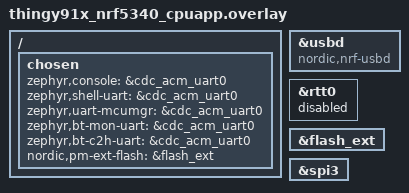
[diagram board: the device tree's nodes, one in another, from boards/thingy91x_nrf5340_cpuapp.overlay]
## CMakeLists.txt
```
#
# Copyright (c) 2022 Nordic Semiconductor ASA
#
# SPDX-License-Identifier: LicenseRef-Nordic-5-Clause
#

cmake_minimum_required(VERSION 3.20.0)

find_package(Zephyr REQUIRED HINTS $ENV{ZEPHYR_BASE})
project(nrf_wifi_sta)

target_include_directories(app PUBLIC ${ZEPHYR_BASE}/subsys/net/ip)

# Add http service
zephyr_linker_sources(SECTIONS sections-rom.ld)
zephyr_linker_section_ifdef(CONFIG_NET_SAMPLE_HTTP_SERVICE NAME
				http_resource_desc_test_http_service
				KVMA RAM_REGION GROUP RODATA_REGION
				SUBALIGN Z_LINK_ITERABLE_SUBALIGN)

# Add static web resources
set(gen_dir ${ZEPHYR_BINARY_DIR}/include/generated/)

foreach(web_resource
  index.html
  main.js
  styles.css
  Color_circle.svg
  Logo_Flat_RGB_Horizontal.svg
  thingy91x.glb
    )
  generate_inc_file_for_target(
    app
    src/static_web_resources/${web_resource}
    ${gen_dir}/${web_resource}.gz.inc
    --gzip
  )
endforeach()

# Generate hex files from pem files
set(gen_dir ${CMAKE_CURRENT_BINARY_DIR}/certs)
zephyr_include_directories(${gen_dir})
generate_inc_file_for_target(
    app
    cert/StarfieldServicesCertG2.pem
    ${gen_dir}/StarfieldServicesCertG2.pem.inc
    )

target_sources(app PRIVATE
	src/main.c
    src/sensors.c
    src/http_resources.c
    src/wifi.c
    src/https_request.c
)
```

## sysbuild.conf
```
#
# Copyright (c) 2024 Nordic Semiconductor ASA
#
# SPDX-License-Identifier: LicenseRef-Nordic-5-Clause
#

SB_CONFIG_WIFI_NRF70=y

SB_CONFIG_THINGY91X_STATIC_PARTITIONS_NRF53_EXTERNAL_FLASH=y
```

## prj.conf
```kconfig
#
# Copyright (c) 2024 Nordic Semiconductor ASA
#
# SPDX-License-Identifier: LicenseRef-Nordic-5-Clause
#

# Optimize TF-M
CONFIG_TFM_PROFILE_TYPE_SMALL=y
CONFIG_PM_PARTITION_SIZE_TFM_SRAM=0xa000
CONFIG_PM_PARTITION_SIZE_TFM=0x20000

# Optimize Wi-Fi stack to save some memory.
CONFIG_HEAP_MEM_POOL_SIZE=120000
CONFIG_HEAP_MEM_POOL_IGNORE_MIN=y
CONFIG_NRF70_RX_NUM_BUFS=16
CONFIG_NRF70_MAX_TX_AGGREGATION=4

# Wi-Fi
CONFIG_WIFI=y
CONFIG_WIFI_NRF70=y
CONFIG_NRF70_AP_MODE=y
CONFIG_WIFI_NM_WPA_SUPPLICANT=y
CONFIG_WIFI_NM_WPA_SUPPLICANT_AP=y
CONFIG_NET_L2_ETHERNET=y
CONFIG_WIFI_CREDENTIALS=y

# General
CONFIG_LOG=y
CONFIG_LOG_MODE_IMMEDIATE=y
CONFIG_ASSERT=y
CONFIG_ASSERT_VERBOSE=n
CONFIG_REBOOT=y

CONFIG_NET_LOG=y
CONFIG_LOG_DEFAULT_LEVEL=3


# Link-time optimizations
CONFIG_LTO=y
CONFIG_ISR_TABLES_LOCAL_DECLARATION=y

# Temporarily enable FS support so that linking succeeds.
CONFIG_FILE_SYSTEM=y
CONFIG_MAIN_STACK_SIZE=6144
CONFIG_NANOPB=y
CONFIG_SMF=y

# HTTP parser
CONFIG_HTTP_PARSER=y
CONFIG_HTTP_PARSER_URL=y

# DK Butons and LEDs
CONFIG_DK_LIBRARY=y

# Networking config
CONFIG_NETWORKING=y
CONFIG_NET_CONNECTION_MANAGER=y
CONFIG_NET_IPV4=y
# Disable IPv6 to save memory
CONFIG_NET_IPV6=n
CONFIG_NET_TCP=y
CONFIG_NET_UDP=y
CONFIG_NET_SOCKETS=y
CONFIG_NET_MAX_CONN=6
CONFIG_ZVFS_OPEN_MAX=20
CONFIG_NET_SOCKETS_TLS_MAX_CONTEXTS=2
CONFIG_NET_SOCKETS_SOCKOPT_TLS=y

# Zephyr NET Connection Manager connectivity layer
CONFIG_L2_WIFI_CONNECTIVITY=y
CONFIG_L2_WIFI_CONNECTIVITY_AUTO_CONNECT=n
CONFIG_L2_WIFI_CONNECTIVITY_AUTO_DOWN=n

# SoftAP Wi-Fi Provision library
CONFIG_SOFTAP_WIFI_PROVISION=y
CONFIG_SOFTAP_WIFI_PROVISION_THREAD_STACK_SIZE=8192
# Disable socket close on completed provisioning to keep mDNS SD running.
# SD depends on the socket being open for a specified port.
CONFIG_SOFTAP_WIFI_PROVISION_SOCKET_CLOSE_ON_COMPLETION=n
CONFIG_SOFTAP_WIFI_PROVISION_LOG_LEVEL_DBG=y

# (M)DNS
CONFIG_MDNS_RESPONDER=y
CONFIG_DNS_SD=y
CONFIG_MDNS_RESPONDER_DNS_SD=y
CONFIG_NET_HOSTNAME_ENABLE=y
CONFIG_NET_HOSTNAME="wifiprov"
# Disable POSIX uname support to suppress build warning that hostname is too long.
CONFIG_POSIX_UNAME=n

# DHCPv4 client and server
CONFIG_NET_DHCPV4=y
CONFIG_NET_DHCPV4_SERVER=y

# Store TLS credentials to protected storage.
CONFIG_TLS_CREDENTIALS=y
CONFIG_TLS_CREDENTIALS_BACKEND_PROTECTED_STORAGE=y

# Disable auto init of NET config as the softAP Wi-Fi provision library will manually set its
# own IP configuration.
CONFIG_NET_CONFIG_AUTO_INIT=n


CONFIG_FLASH=y
CONFIG_FLASH_MAP=y
CONFIG_NVS=y
CONFIG_SETTINGS=y
CONFIG_SETTINGS_NVS=y
```

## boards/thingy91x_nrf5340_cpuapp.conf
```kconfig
CONFIG_SPI=y
CONFIG_FLASH=y
CONFIG_SPI_NOR=y
CONFIG_SPI_NOR_FLASH_LAYOUT_PAGE_SIZE=4096
CONFIG_SPI_NOR_SFDP_DEVICETREE=y
CONFIG_I2C=y

CONFIG_NFCT_PINS_AS_GPIOS=y


# USB
CONFIG_USB_DEVICE_STACK=y
CONFIG_USB_DEVICE_PRODUCT="Thingy:91x USB Logging"
CONFIG_USB_CDC_ACM=y
CONFIG_USB_COMPOSITE_DEVICE=y
CONFIG_USB_MASS_STORAGE=n
CONFIG_USB_DEVICE_MANUFACTURER="Nordic Semiconductor"
CONFIG_USB_DEVICE_VID=0x1915
CONFIG_USB_DEVICE_PID=0x910A

CONFIG_USB_DEVICE_REMOTE_WAKEUP=n
CONFIG_USB_DEVICE_INITIALIZE_AT_BOOT=y

CONFIG_USE_SEGGER_RTT=n
CONFIG_RTT_CONSOLE=n

CONFIG_FW_INFO=y
CONFIG_SECURE_BOOT_STORAGE=y


CONFIG_FLASH=y
CONFIG_FLASH_MAP=y
CONFIG_NVS=y
CONFIG_SETTINGS=y
CONFIG_SETTINGS_NVS=y
```

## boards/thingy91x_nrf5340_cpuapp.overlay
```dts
/* Copyright (c) 2024 Nordic Semiconductor ASA
 *
 * SPDX-License-Identifier: LicenseRef-Nordic-5-Clause
 */

 #include <thingy91x_nrf53_wifi.dtsi>

 &usbd {
     compatible = "nordic,nrf-usbd";
     status = "okay";
 };
 
 / {
     chosen {
         zephyr,console = &cdc_acm_uart0;
         zephyr,shell-uart = &cdc_acm_uart0;
         zephyr,uart-mcumgr = &cdc_acm_uart0;
         zephyr,bt-mon-uart = &cdc_acm_uart0;
         zephyr,bt-c2h-uart = &cdc_acm_uart0;
         nordic,pm-ext-flash = &flash_ext;
     };
 };
 
 &rtt0 {
     status = "disabled";
 };
 
 
 /* Enable external flash */
 &flash_ext{
     status = "okay";
 };
 
 &spi3{
     status = "okay";
 };
```

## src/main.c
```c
/*
 * Copyright (c) 2022 Nordic Semiconductor ASA
 *
 * SPDX-License-Identifier: LicenseRef-Nordic-5-Clause
 */

/** @file
 * @brief WiFi station sample
 */

#include <zephyr/logging/log.h>
LOG_MODULE_REGISTER(http_server, CONFIG_LOG_DEFAULT_LEVEL);

#include <zephyr/kernel.h>
#include <stdio.h>
#include <stdlib.h>
#include <zephyr/shell/shell.h>
#include <zephyr/init.h>

#include <dk_buttons_and_leds.h>
#include <zephyr/device.h>
#include <zephyr/drivers/pwm.h>

#include <zephyr/data/json.h>

#include <zephyr/net/socket.h>
#include <zephyr/net/websocket.h>

#include <zephyr/sys/reboot.h>

#include "sensors.h"
#include "http_resources.h"
#include "wifi.h"
#include "https_request.h"

#ifdef CONFIG_SYS_HEAP_LISTENER
#include <zephyr/sys/heap_listener.h>
extern struct sys_heap _system_heap;
struct sys_memory_stats system_heap_stats;
uint32_t system_heap_free = 0;
uint32_t system_heap_used = 0;
uint32_t system_heap_max_used = 0;

void on_system_heap_alloc(uintptr_t heap_id, void *mem, size_t bytes)
{
	if (heap_id == HEAP_ID_FROM_POINTER(&_system_heap)) {
		sys_heap_runtime_stats_get((struct sys_heap *)&_system_heap.heap,
					   &system_heap_stats);
		system_heap_used = (uint32_t)system_heap_stats.allocated_bytes;
		system_heap_max_used = (uint32_t)system_heap_stats.max_allocated_bytes;
		system_heap_free = (uint32_t)system_heap_stats.free_bytes;
		LOG_INF("system_heap ALLOC %zu. Heap state: allocated %zu, free %zu, max allocated "
			"%zu, heap size %u.\n",
			bytes, system_heap_used, system_heap_free, system_heap_max_used,
			K_HEAP_MEM_POOL_SIZE);
	}
}

void on_system_heap_free(uintptr_t heap_id, void *mem, size_t bytes)
{
	if (heap_id == HEAP_ID_FROM_POINTER(&_system_heap)) {
		sys_heap_runtime_stats_get((struct sys_heap *)&_system_heap.heap,
					   &system_heap_stats);
		system_heap_used = (uint32_t)system_heap_stats.allocated_bytes;
		system_heap_max_used = (uint32_t)system_heap_stats.max_allocated_bytes;
		system_heap_free = (uint32_t)system_heap_stats.free_bytes;
		LOG_INF("system_heap ALLOC %zu. Heap state: allocated %zu, free %zu, max allocated "
			"%zu, heap size %u.\n",
			bytes, system_heap_used, system_heap_free, system_heap_max_used,
			K_HEAP_MEM_POOL_SIZE);
	}
}

HEAP_LISTENER_ALLOC_DEFINE(system_heap_listener_alloc, HEAP_ID_FROM_POINTER(&_system_heap),
			   on_system_heap_alloc);
HEAP_LISTENER_FREE_DEFINE(system_heap_listener_free, HEAP_ID_FROM_POINTER(&_system_heap),
			  on_system_heap_free);
#endif // CONFIG_SYS_HEAP_LISTENER

static const struct pwm_dt_spec red_pwm_led = PWM_DT_SPEC_GET(DT_ALIAS(pwm_led0));
static const struct pwm_dt_spec green_pwm_led = PWM_DT_SPEC_GET(DT_ALIAS(pwm_led1));
static const struct pwm_dt_spec blue_pwm_led = PWM_DT_SPEC_GET(DT_ALIAS(pwm_led2));

uint8_t apply_gamma(uint8_t value, float gamma)
{
	/* (value/255)^gamma * 255 */
	return (uint8_t)(pow(value / 255.0, gamma) * 255);
}

int pwm_set_color(int red, int green, int blue)
{
	int ret;

	/* Parameters to adjust intensity of each color */
	float red_gamma = 2.2;
	float green_gamma = 2.2;
	float blue_gamma = 2.2;

	float red_intensity_scale = 1.0;
	float green_intensity_scale = 1.0;
	float blue_intensity_scale = 0.8;

	// LOG_DBG("PWM_Color: Red: %d, Green: %d, Blue: %d \n", red, green, blue);

	// Apply gamma correction
	int corrected_red = apply_gamma(red * red_intensity_scale, red_gamma);
	int corrected_green = apply_gamma(green * green_intensity_scale, green_gamma);
	int corrected_blue = apply_gamma(blue * blue_intensity_scale, blue_gamma);

	// uint32_t period = red_pwm_led.period;
	int pwm_red = (corrected_red * red_pwm_led.period) / 255;
	int pwm_green = (corrected_green * green_pwm_led.period) / 255;
	int pwm_blue = (corrected_blue * blue_pwm_led.period) / 255;

	ret = pwm_set_pulse_dt(&red_pwm_led, pwm_red);
	if (ret != 0) {
		LOG_ERR("Error %d: red write failed\n", ret);
		return ret;
	}

	ret = pwm_set_pulse_dt(&green_pwm_led, pwm_green);
	if (ret != 0) {
		LOG_ERR("Error %d: green write failed\n", ret);
		return ret;
	}

	ret = pwm_set_pulse_dt(&blue_pwm_led, pwm_blue);
	if (ret != 0) {
		LOG_ERR("Error %d: blue write failed\n", ret);
		return ret;
	}

	return 0;
}

static void sensor_handler(struct k_work *work)
{
	int ret;
	static char tx_buf[1024];
	struct k_work_delayable *dwork = k_work_delayable_from_work(work);
	struct ws_sensors_ctx *ctx = CONTAINER_OF(dwork, struct ws_sensors_ctx, work);

	// ret = sensors_collect(tx_buf, sizeof(tx_buf));
	ret = sensors_get_json(tx_buf, sizeof(tx_buf));
	if (ret < 0) {
		LOG_ERR("Unable to collect sensor data, err %d", ret);
		goto unregister;
	}

	ret = websocket_send_msg(ctx->sock, tx_buf, ret, WEBSOCKET_OPCODE_DATA_TEXT, false, true,
				 SYS_FOREVER_MS);
	if (ret < 0) {
		LOG_INF("Couldn't send websocket msg (%d), closing connection", ret);
		goto unregister;
	}

	ret = k_work_reschedule(&ctx->work, K_MSEC(CONFIG_NET_SAMPLE_WEBSOCKET_SENSOR_INTERVAL));
	if (ret < 0) {
		LOG_ERR("Failed to schedule sensor work, err %d", ret);
		goto unregister;
	}

	return;

unregister:
	(void)websocket_unregister(ctx->sock);
	ctx->sock = -1;
}

int ws_sensors_init(void)
{
	struct ws_sensors_ctx *ctx = NULL;
	http_resources_get_ws_ctx(&ctx);

	for (int i = 0; i < CONFIG_NET_SAMPLE_NUM_WEBSOCKET_HANDLERS; i++) {
		ctx[i].sock = -1;
		k_work_init_delayable(&ctx[i].work, sensor_handler);
	}

	return 0;
}
SYS_INIT(ws_sensors_init, APPLICATION, 0);

static int get_free_sensor_slot(void)
{
	struct ws_sensors_ctx *ctx = NULL;
	http_resources_get_ws_ctx(&ctx);

	for (int i = 0; i < CONFIG_NET_SAMPLE_NUM_WEBSOCKET_HANDLERS; i++) {
		if (ctx[i].sock < 0) {
			return i;
		}
	}

	return -1;
}

int ws_sensors_setup(int ws_socket, void *user_data)
{
	ARG_UNUSED(user_data);

	struct ws_sensors_ctx *ctx = NULL;
	http_resources_get_ws_ctx(&ctx);

	int slot = get_free_sensor_slot();
	if (slot < 0) {
		LOG_ERR("No free slot for sensor websocket");
		return -ENOMEM;
	}
	LOG_INF("Setting up sensor websocket on slot %d", slot);

	ctx[slot].sock = ws_socket;

	LOG_INF("Using socket %d for sensor websocket", ws_socket);

	int ret = k_work_reschedule(&ctx[slot].work, K_NO_WAIT);
	if (ret < 0) {
		LOG_ERR("Failed to reschedule sensor work");
		return ret;
	}

	LOG_INF("Sensor websocket setup on slot %d", slot);

	return 0;
}

static void parse_led_post(uint8_t *buf, size_t len)
{
	int ret;
	struct led_command cmd;
	const int expected_return_code = BIT_MASK(ARRAY_SIZE(led_command_descr));

	LOG_DBG("Got POST request with payload: %s", buf);

	ret = json_obj_parse(buf, len, led_command_descr, ARRAY_SIZE(led_command_descr), &cmd);
	if (ret != expected_return_code) {
		LOG_WRN("Failed to fully parse JSON payload, ret=%d", ret);
		return;
	}

	ret = pwm_set_color(cmd.r, cmd.g, cmd.b);
	if (ret) {
		LOG_ERR("Failed to set LED color");
	}
}

static int led_handler(struct http_client_ctx *client, enum http_data_status status,
		       uint8_t *buffer, size_t len, void *user_data)
{
	ARG_UNUSED(client);
	ARG_UNUSED(user_data);

	static uint8_t post_payload_buf[32];
	static size_t cursor;

	LOG_DBG("LED handler status %d, size %zu", status, len);

	if (status == HTTP_SERVER_DATA_ABORTED) {
		cursor = 0;
		return 0;
	}

	if (len + cursor > sizeof(post_payload_buf)) {
		cursor = 0;
		return -ENOMEM;
	}

	/* Copy payload to our buffer. Note that even for a small payload, it may arrive split into
	 * chunks (e.g. if the header size was such that the whole HTTP request exceeds the size of
	 * the client buffer).
	 */
	memcpy(post_payload_buf + cursor, buffer, len);
	cursor += len;

	if (status == HTTP_SERVER_DATA_FINAL) {
		parse_led_post(post_payload_buf, cursor);
		cursor = 0;
	}

	return 0;
}

static void parse_jwt_post(uint8_t *buf, size_t len)
{
	ARG_UNUSED((len));

	int ret;

	ret = pwm_set_color(255, 255, 0);
	if (ret) {
		LOG_ERR("Failed to set LED color");
	}

	// Manually phrasing the JSON payload
	char temp_buff[512] = {0};
	// Remove leading {"jwt":"
	ret = snprintf(temp_buff, sizeof(temp_buff), "%s", buf + 8);
	if (ret < 0) {
		LOG_ERR("Failed to format JWT\n");
		return;
	}
	// Remove trailing "}
	temp_buff[ret - 2] = '\0';

	char location_str[256];
	memset(location_str, 0, sizeof(location_str));

	char api_str[CONFIG_WIFI_SCAN_STR_MAX_MAC_ADDR * 65];

	get_nrfcloud_api_str(api_str, sizeof(api_str));

	send_http_request(location_str, sizeof(location_str), api_str, sizeof(api_str), temp_buff);

	http_resources_set_location(location_str);

	ret = pwm_set_color(0, 255, 0);
	if (ret) {
		LOG_ERR("Failed to set LED color");
	}
}

static int jwt_handler(struct http_client_ctx *client, enum http_data_status status,
		       uint8_t *buffer, size_t len, void *user_data)
{

	ARG_UNUSED(client);
	ARG_UNUSED(user_data);

	static uint8_t post_payload_buf[512];
	static size_t cursor;

	if (status == HTTP_SERVER_DATA_ABORTED) {
		cursor = 0;
		return 0;
	}

	if (len + cursor > sizeof(post_payload_buf)) {
		cursor = 0;
		LOG_ERR("Buffer overflow");
		return -ENOMEM;
	}

	/* Copy payload to our buffer. Note that even for a small payload, it may arrive split into
	 * chunks (e.g. if the header size was such that the whole HTTP request exceeds the size of
	 * the client buffer).
	 */
	memcpy(post_payload_buf + cursor, buffer, len);
	cursor += len;
	LOG_INF("JWT handler cursor %zu", cursor);

	if (status == HTTP_SERVER_DATA_FINAL) {
		parse_jwt_post(post_payload_buf, cursor);
		memset(post_payload_buf, 0, sizeof(post_payload_buf));
		// Clear the buffer after processing
		cursor = 0;
	}

	return 0;
}

/**
 * @brief Function called when buttons are pressed.
 */
static void button_handler(uint32_t button_state, uint32_t has_changed)
{
	if (has_changed & DK_BTN1_MSK) {
		if (button_state & DK_BTN1_MSK) {
			LOG_INF("Button 1 pressed");
			sys_reboot(SYS_REBOOT_COLD); // Reset the device
		}
	}
}

/**
 * @brief Function called when Wi-Fi is connected.
 */
static void wifi_connected_handler(void)
{
	LOG_INF("Wi-Fi connected");

	LOG_INF("HTTP server staring");
	http_server_start();

	int ret = pwm_set_color(0, 255, 0);
	if (ret) {
		LOG_ERR("Failed to set LED color");
	}
}

static int location_handler(struct http_client_ctx *client, enum http_data_status status,
			    uint8_t *buffer, size_t len, void *user_data)
{
	ARG_UNUSED(client);
	ARG_UNUSED(len);
	ARG_UNUSED(user_data);

	static bool response_sent;
	extern char location_buf[256];

	switch (status) {
	case HTTP_SERVER_DATA_ABORTED: {
		response_sent = false;
		return 0;
	}

	case HTTP_SERVER_DATA_MORE: {
		/* A payload is not expected with the GET request. Ignore any data and wait until
		 * final callback before sending response
		 */
		return 0;
	}

	case HTTP_SERVER_DATA_FINAL: {
		if (response_sent) {
			/* Response already sent, return 0 to indicate to server that the callback
			 * does not need to be called again.
			 */
			response_sent = false;
			return 0;
		}

		response_sent = true;
		return snprintf(buffer, sizeof(location_buf), "%s", location_buf);
	}
	default: {
		LOG_WRN("Unexpected status %d", status);
		return -1;
	}
	}
}

int main(void)
{
	int ret = 0;

	// ret = dk_leds_init();
	// if (ret != 0) {
	// 	LOG_ERR("Failed to initialize LEDs");
	// 	return -1;
	// }

	if (!pwm_is_ready_dt(&red_pwm_led) || !pwm_is_ready_dt(&green_pwm_led) ||
	    !pwm_is_ready_dt(&blue_pwm_led)) {
		LOG_ERR("Error: one or more PWM devices not ready\n");
		return 0;
	}

	ret = pwm_set_color(255, 0, 0);
	if (ret) {
		LOG_ERR("Failed to set LED color");
	}

	ret = dk_buttons_init(button_handler);
	if (ret != 0) {
		LOG_ERR("Failed to initialize buttons");
		return -1;
	}

	ret = sensors_init();
	if (ret) {
		LOG_ERR("Failed to initialize sensors");
		return ret;
	}

	/* Provision certificates before connecting to the network */
	ret = cert_provision();
	if (ret) {
		return 0;
	}

	http_resources_set_led_handler(led_handler);
	http_resources_set_jwt_handler(jwt_handler);
	http_resources_set_ws_handler(ws_sensors_setup);
	wifi_sta_set_wifi_connected_cb(wifi_connected_handler);
	http_resources_set_location_handler(location_handler);

#ifdef CONFIG_SYS_HEAP_LISTENER
	heap_listener_register(&system_heap_listener_alloc);
	heap_listener_register(&system_heap_listener_free);
#endif // CONFIG_SYS_HEAP_LISTENER

	net_mgmt_callback_init();

	ret = wifi_scan();
	if (ret) {
		LOG_ERR("Failed to scan for Wi-Fi networks, err %d", ret);
		return ret;
	}

#ifdef CONFIG_WIFI_READY_LIB
	ret = register_wifi_ready();
	if (ret) {
		return ret;
	}
	k_thread_start(wifi_sta_get_start_wifi_thread_id());
#else
	start_app();
#endif /* CONFIG_WIFI_READY_LIB */

	return ret;
}
```

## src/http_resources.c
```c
#include "http_resources.h"

//////////////////////////////////////// HTTP Service //////////////////////////////////////////

static uint16_t test_http_service_port = CONFIG_NET_SAMPLE_HTTP_SERVER_SERVICE_PORT;
HTTP_SERVICE_DEFINE(test_http_service, NULL, &test_http_service_port, 1, 10, NULL);

//////////////////////////////////////// HTTP Resources //////////////////////////////////////////

////////////////// Index HTML //////////////////
// This is the main HTML file that is loaded by the browser.

static const uint8_t index_html_gz[] = {
#include "index.html.gz.inc"
};

struct http_resource_detail_static index_html_gz_resource_detail = {
	.common =
		{
			.type = HTTP_RESOURCE_TYPE_STATIC,
			.bitmask_of_supported_http_methods = BIT(HTTP_GET),
			.content_encoding = "gzip",
			.content_type = "text/html",
		},
	.static_data = index_html_gz,
	.static_data_len = sizeof(index_html_gz),
};

HTTP_RESOURCE_DEFINE(index_html_gz_resource, test_http_service, "/",
		     &index_html_gz_resource_detail);

////////////////// Main JS //////////////////
// This is the main JavaScript file that is loaded by the index.html file.

static const uint8_t main_js_gz[] = {
#include "main.js.gz.inc"
};

struct http_resource_detail_static main_js_gz_resource_detail = {
	.common =
		{
			.type = HTTP_RESOURCE_TYPE_STATIC,
			.bitmask_of_supported_http_methods = BIT(HTTP_GET),
			.content_encoding = "gzip",
			.content_type = "application/javascript",
		},
	.static_data = main_js_gz,
	.static_data_len = sizeof(main_js_gz),
};

HTTP_RESOURCE_DEFINE(main_js_gz_resource, test_http_service, "/main.js",
		     &main_js_gz_resource_detail);

////////////////// styles CSS //////////////////
// This is the CSS file that is loaded by the index.html file.

static const uint8_t styles_css_gz[] = {
#include "styles.css.gz.inc"
};

struct http_resource_detail_static styles_css_gz_resource_detail = {
	.common =
		{
			.type = HTTP_RESOURCE_TYPE_STATIC,
			.bitmask_of_supported_http_methods = BIT(HTTP_GET),
			.content_encoding = "gzip",
			.content_type = "text/css",
		},
	.static_data = styles_css_gz,
	.static_data_len = sizeof(styles_css_gz),
};

HTTP_RESOURCE_DEFINE(styles_css_gz_resource, test_http_service, "/styles.css",
		     &styles_css_gz_resource_detail);

////////////////// Color circle svg //////////////////
// This is an image to be displayed in the browser.

static const uint8_t color_circle_gz[] = {
#include "Color_circle.svg.gz.inc"
};

struct http_resource_detail_static color_circle_gz_resource_detail = {
	.common =
		{
			.type = HTTP_RESOURCE_TYPE_STATIC,
			.bitmask_of_supported_http_methods = BIT(HTTP_GET),
			.content_encoding = "gzip",
			.content_type = "image/svg+xml",
		},
	.static_data = color_circle_gz,
	.static_data_len = sizeof(color_circle_gz),
};

HTTP_RESOURCE_DEFINE(color_circle_gz_resource, test_http_service, "/Color_circle.svg",
		     &color_circle_gz_resource_detail);

////////////////// Logo Nordic svg //////////////////
// This is an image to be displayed in the browser.

static const uint8_t logo_Nordic_svg_gz[] = {
#include "Logo_Flat_RGB_Horizontal.svg.gz.inc"
};

struct http_resource_detail_static logo_Nordic_svg_gz_resource_detail = {
	.common =
		{
			.type = HTTP_RESOURCE_TYPE_STATIC,
			.bitmask_of_supported_http_methods = BIT(HTTP_GET),
			.content_encoding = "gzip",
			.content_type = "image/svg+xml",
		},
	.static_data = logo_Nordic_svg_gz,
	.static_data_len = sizeof(logo_Nordic_svg_gz),
};

HTTP_RESOURCE_DEFINE(logo_Nordic_svg_gz_resource, test_http_service,
		     "/Logo_Flat_RGB_Horizontal.svg", &logo_Nordic_svg_gz_resource_detail);

////////////////// 3D Model //////////////////
// This is an 3D model to be displayed in the browser.

static const uint8_t model_glb_gz[] = {
// #include "Duck.glb.gz.inc"
#include "thingy91x.glb.gz.inc"
};

struct http_resource_detail_static model_glb_gz_resource_detail = {
	.common =
		{
			.type = HTTP_RESOURCE_TYPE_STATIC,
			.bitmask_of_supported_http_methods = BIT(HTTP_GET),
			.content_encoding = "gzip",
			.content_type = "model/gltf-binary",
		},
	.static_data = model_glb_gz,
	.static_data_len = sizeof(model_glb_gz),
};

HTTP_RESOURCE_DEFINE(model_glb_gz_resource, test_http_service, "/thingy91x.glb",
		     &model_glb_gz_resource_detail);

////////////////// LED Resource //////////////////
// This is the resource that is used to control the LEDs on the Thingy:91x.
// It is a dynamic resource that accepts POST requests with JSON payloads.

static uint8_t led_buf[256]; // Buffer to store the JSON payload

static struct http_resource_detail_dynamic led_resource_detail = {
	.common =
		{
			.type = HTTP_RESOURCE_TYPE_DYNAMIC,
			.bitmask_of_supported_http_methods = BIT(HTTP_POST),
		},
	.cb = NULL, // This is set by the http_resources_set_led_handler function to allow callback
		    // function to be defined in main.c
	.data_buffer = led_buf,
	.data_buffer_len = sizeof(led_buf),
	.user_data = NULL,
};

HTTP_RESOURCE_DEFINE(led_resource, test_http_service, "/led", &led_resource_detail);

void http_resources_set_led_handler(http_resource_dynamic_cb_t handler)
{
	led_resource_detail.cb = handler;
}

///////////////////// JWT Resource //////////////////
// This is the resource that is used to get the JWT token from the server.
// It is a dynamic resource that accepts POST requests with JSON payloads.

static uint8_t jwt_buf[512]; // Buffer to store the JSON payload
static struct http_resource_detail_dynamic jwt_resource_detail = {
	.common =
		{
			.type = HTTP_RESOURCE_TYPE_DYNAMIC,
			.bitmask_of_supported_http_methods = BIT(HTTP_POST),
		},
	.cb = NULL, // This is set by the http_resources_set_jwt_handler function to allow callback
		    // function to be defined in main.c
	.data_buffer = jwt_buf,
	.data_buffer_len = sizeof(jwt_buf),
	.user_data = NULL,
};

HTTP_RESOURCE_DEFINE(jwt_resource, test_http_service, "/jwt", &jwt_resource_detail);

void http_resources_set_jwt_handler(http_resource_dynamic_cb_t handler)
{
	jwt_resource_detail.cb = handler;
}

////////////////// WebSocket Resource //////////////////
// This is the resource that is used to send sensor data over a WebSocket connection.

static struct ws_sensors_ctx sensors_ctx[CONFIG_NET_SAMPLE_NUM_WEBSOCKET_HANDLERS];

static uint8_t ws_netstats_buffer[128];

struct http_resource_detail_websocket ws_netstats_resource_detail = {
	.common =
		{
			.type = HTTP_RESOURCE_TYPE_WEBSOCKET,
			/* We need HTTP/1.1 Get method for upgrading */
			.bitmask_of_supported_http_methods = BIT(HTTP_GET),
		},
	.cb = NULL, // This is set by the http_resources_set_ws_handler function to allow callback
		    // function to be defined in main.c
	.data_buffer = ws_netstats_buffer,
	.data_buffer_len = sizeof(ws_netstats_buffer),
	.user_data = NULL,
};

HTTP_RESOURCE_DEFINE(ws_netstats_resource, test_http_service, "/", &ws_netstats_resource_detail);

void http_resources_set_ws_handler(http_resource_websocket_cb_t handler)
{
	ws_netstats_resource_detail.cb = handler;
}

void http_resources_get_ws_ctx(struct ws_sensors_ctx **ctx)
{
	*ctx = sensors_ctx;
}

////////////////// Location Resource //////////////////
// GET /location
// This is a dynamic resource that returns the location of the device.

uint8_t location_buf[256]; // Buffer to store the location

static struct http_resource_detail_dynamic location_resource_detail = {
	.common =
		{
			.type = HTTP_RESOURCE_TYPE_DYNAMIC,
			.bitmask_of_supported_http_methods = BIT(HTTP_GET),
		},
	.cb = NULL, // This is set by the http_resources_set_location_handler function to allow
		    // callback function to be defined in main.c
	.data_buffer = location_buf,
	.data_buffer_len = sizeof(location_buf),
	.user_data = NULL,
};

HTTP_RESOURCE_DEFINE(location_resource, test_http_service, "/location", &location_resource_detail);

void http_resources_set_location_handler(http_resource_dynamic_cb_t handler)
{
	location_resource_detail.cb = handler;
}

void http_resources_set_location(const char *location)
{
	strncpy(location_buf, location, sizeof(location_buf));
}
```

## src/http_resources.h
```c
#pragma once

#include <zephyr/net/http/server.h>
#include <zephyr/net/http/service.h>
#include <zephyr/data/json.h>

struct ws_sensors_ctx {
	int sock;
	struct k_work_delayable work;
};

struct led_command {
	int r;
	int g;
	int b;
};

static const struct json_obj_descr led_command_descr[] = {
	JSON_OBJ_DESCR_PRIM(struct led_command, r, JSON_TOK_NUMBER),
	JSON_OBJ_DESCR_PRIM(struct led_command, g, JSON_TOK_NUMBER),
	JSON_OBJ_DESCR_PRIM(struct led_command, b, JSON_TOK_NUMBER),
};

struct jwt_command {
	char jwt[512];
};

static const struct json_obj_descr jwt_command_descr[] = {
	JSON_OBJ_DESCR_PRIM(struct jwt_command, jwt, JSON_TOK_STRING),
};

void http_resources_set_led_handler(http_resource_dynamic_cb_t handler);
void http_resources_set_jwt_handler(http_resource_dynamic_cb_t handler);
void http_resources_set_ws_handler(http_resource_websocket_cb_t handler);
void http_resources_get_ws_ctx(struct ws_sensors_ctx **ctx);
void http_resources_set_location_handler(http_resource_dynamic_cb_t handler);
void http_resources_set_location(const char *location);
```

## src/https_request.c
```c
#include "https_request.h"

#include <zephyr/logging/log.h>
LOG_MODULE_REGISTER(HTTPS_REQUEST, CONFIG_WIFI_STA_LOG_LEVEL);

// Define a buffer large enough to hold headers and body
#define SEND_BUF_SIZE 1024
#define RECV_BUF_SIZE 2048
static char recv_buf[RECV_BUF_SIZE];

#define HTTPS_PORT "443"
#define POST_URL "/v1/location/wifi"
#define TLS_SEC_TAG 42

static const char cert[] = {
#include "StarfieldServicesCertG2.pem.inc"

	/* Null terminate certificate if running Mbed TLS on the application core.
	 * Required by TLS credentials API.
	 */
	IF_ENABLED(CONFIG_TLS_CREDENTIALS, (0x00))};

/* Provision certificate to modem */
int cert_provision(void)
{
	int err;

	LOG_INF("Provisioning certificate\n");

	err = tls_credential_add(TLS_SEC_TAG, TLS_CREDENTIAL_CA_CERTIFICATE, cert, sizeof(cert));
	if (err == -EEXIST) {
		LOG_WRN("CA certificate already exists, sec tag: %d\n", TLS_SEC_TAG);
	} else if (err < 0) {
		LOG_ERR("Failed to register CA certificate: %d\n", err);
		return err;
	}

	return 0;
}

/* Setup TLS options on a given socket */
int tls_setup(int fd)
{
	int err;
	int verify;

	/* Security tag that we have provisioned the certificate with */
	const sec_tag_t tls_sec_tag[] = {
		TLS_SEC_TAG,
	};

	/* Set up TLS peer verification */
	enum {
		NONE = 0,
		OPTIONAL = 1,
		REQUIRED = 2,
	};

	verify = REQUIRED;

	err = setsockopt(fd, SOL_TLS, TLS_PEER_VERIFY, &verify, sizeof(verify));
	if (err) {
		LOG_ERR("Failed to setup peer verification, err %d\n", errno);
		return err;
	}

	/* Associate the socket with the security tag
	 * we have provisioned the certificate with.
	 */
	err = setsockopt(fd, SOL_TLS, TLS_SEC_TAG_LIST, tls_sec_tag, sizeof(tls_sec_tag));
	if (err) {
		LOG_ERR("Failed to setup TLS sec tag, err %d\n", errno);
		return err;
	}

	err = setsockopt(fd, SOL_TLS, TLS_HOSTNAME, CONFIG_HTTPS_HOSTNAME,
			 sizeof(CONFIG_HTTPS_HOSTNAME) - 1);
	if (err) {
		LOG_ERR("Failed to setup TLS hostname, err %d\n", errno);
		return err;
	}
	return 0;
}

void send_http_request(char *location_str, size_t location_str_len, char *api_str,
		       size_t api_str_len, char *auth_token)
{
	int err;
	int fd;
	int bytes;
	size_t off;
	struct addrinfo *res;
	struct addrinfo hints = {
		.ai_flags = AI_NUMERICSERV, /* Let getaddrinfo() set port */
		.ai_socktype = SOCK_STREAM,
	};
	char peer_addr[INET6_ADDRSTRLEN];

	// Clear location string
	memset(location_str, 0, location_str_len);

	LOG_INF("Looking up %s\n", CONFIG_HTTPS_HOSTNAME);

	// NOTE: Multiple DNS attempts inorder to deal with unstable network such as mobile hotspots
	for (int i = 0; i < CONFIG_DNS_ATTEMPTS; i++) {
		err = getaddrinfo(CONFIG_HTTPS_HOSTNAME, HTTPS_PORT, &hints, &res);
		if (err) {
			if (i == CONFIG_DNS_ATTEMPTS - 1) {
				LOG_ERR("getaddrinfo() failed, errno %d, err %d\n", errno, err);
				return;
			}
			LOG_WRN("getaddrinfo() failed, errno %d, err %d\n", errno, err);
		} else {
			break;
		}
	}

	inet_ntop(res->ai_family, &((struct sockaddr_in *)(res->ai_addr))->sin_addr, peer_addr,
		  INET6_ADDRSTRLEN);
	LOG_INF("Resolved %s (%s)\n", peer_addr, net_family2str(res->ai_family));

	if (IS_ENABLED(CONFIG_SAMPLE_TFM_MBEDTLS)) {
		fd = socket(res->ai_family, SOCK_STREAM | SOCK_NATIVE_TLS, IPPROTO_TLS_1_2);
	} else {
		fd = socket(res->ai_family, SOCK_STREAM, IPPROTO_TLS_1_2);
	}
	if (fd == -1) {
		LOG_ERR("Failed to open socket!\n");
		goto clean_up;
	}

	/* Setup TLS socket options */
	err = tls_setup(fd);
	if (err) {
		goto clean_up;
	}

	LOG_INF("Connecting to %s:%d\n", CONFIG_HTTPS_HOSTNAME,
		ntohs(((struct sockaddr_in *)(res->ai_addr))->sin_port));
	err = connect(fd, res->ai_addr, res->ai_addrlen);
	if (err) {
		LOG_ERR("connect() failed, err: %d\n", errno);
		goto clean_up;
	}

	char send_buf[SEND_BUF_SIZE];

	// // Remove trailing comma of the api string
	api_str[strlen(api_str) - 1] = '\0';

	// Combine the JSON body string
	char json_body[1024];
	int json_body_len =
		snprintf(json_body, sizeof(json_body), "{\"accessPoints\":[%s]}", api_str);

	// LOG_WRN("JSON body length: %d", json_body_len);

	// Formatted HTTP headers and body
	int header_len = snprintf(send_buf, sizeof(send_buf),
				  "POST %s HTTP/1.1\r\n"
				  "Host: %s:%s\r\n"
				  "Authorization: Bearer %s\r\n"
				  "Content-Type: application/json\r\n"
				  "Content-Length: %zu\r\n"
				  "Connection: close\r\n\r\n"
				  "%s",
				  POST_URL, CONFIG_HTTPS_HOSTNAME, HTTPS_PORT, auth_token,
				  json_body_len, json_body);

	// Check for truncation
	if (header_len < 0 || header_len >= sizeof(send_buf)) {
		LOG_ERR("Error: HTTP request buffer too small!\n");
		return;
	}

	// Debug: Print HTTP request content
	LOG_INF("%s\n", send_buf);

	off = 0;
	do {
		bytes = send(fd, &send_buf[off], header_len - off,
			     0); // Send dynamically formatted buffer
		if (bytes < 0) {
			LOG_ERR("send() failed, err %d\n", errno);
			return;
		}
		off += bytes;
	} while (off < header_len);

	// LOG_INF("Sent %d bytes\n", off);

	off = 0;
	do {
		bytes = recv(fd, &recv_buf[off], RECV_BUF_SIZE - off, 0);
		if (bytes < 0) {
			LOG_ERR("recv() failed, err %d\n", errno);
			goto clean_up;
		}
		off += bytes;

	} while (bytes != 0 /* peer closed connection */);

	// LOG_INF("Received %d bytes\n", off);

	/* Make sure recv_buf is NULL terminated (for safe use with strstr) */
	if (off < sizeof(recv_buf)) {
		recv_buf[off] = '\0';
	} else {
		recv_buf[sizeof(recv_buf) - 1] = '\0';
	}

	// Get the HTTP response code
	char *response_code = strstr(recv_buf, "HTTP/1.1 ");
	int http_response_code = 0;
	if (response_code) {
		response_code += strlen("HTTP/1.1 ");
		char *end_of_code = strstr(response_code, " ");
		if (end_of_code) {
			*end_of_code = '\0'; // Temporarily terminate the string
			// LOG_WRN("HTTP Response Code: %s\n", response_code);
			http_response_code = atoi(response_code);
			*end_of_code = ' '; // Restore the space
		} else {
			LOG_ERR("Could not find end of HTTP response code.\n");
		}
	} else {
		LOG_ERR("Could not find HTTP response code.\n");
	}

	char *header_end = strstr(recv_buf, "\r\n\r\n"); // Locate the end of headers
	if (header_end) {
		LOG_INF("========================================");
		LOG_INF("HTTP Headers:");
		*header_end = '\0';        // Temporarily terminate at the end of headers
		LOG_INF("%s\n", recv_buf); // Print headers
		LOG_INF("========================================");
		LOG_INF("HTTP Body:");
		LOG_INF("%s\n", header_end + 4); // Print the body after separating headers
		LOG_INF("========================================");
	} else {
		LOG_WRN("Could not find end of headers.\n");
	}

	LOG_INF("Finished, closing socket.\n");

	int ret = 0;

	switch (http_response_code) {
	case 200:
		ret = snprintf(location_str, location_str_len, "%s", header_end + 4);
		break;
	case 400:
		LOG_ERR("Bad Request: %s", header_end + 4);
		memcpy(location_str, "{\"message\": \"Bad Request\"}",
		       sizeof("{\"message\": \"Bad Request\"}"));
		break;
	case 401:
		LOG_ERR("Unauthorized: %s", header_end + 4);
		ret = snprintf(location_str, location_str_len, "%s", header_end + 4);
		break;
	case 403:
		LOG_ERR("Forbidden: %s", header_end + 4);
		memcpy(location_str, "{\"message\": \"Forbidden\"}",
		       sizeof("{\"message\": \"Forbidden\"}"));
		break;
	case 404:
		LOG_ERR("Not Found: %s", header_end + 4);
		memcpy(location_str, "{\"message\": \"Location not found\"}",
		       sizeof("{\"message\": \"Location not found\"}"));
		break;
	case 500:
		LOG_ERR("Internal Server Error: %s", header_end + 4);
		memcpy(location_str, "{\"message\": \"Internal Server Error\"}",
		       sizeof("{\"message\": \"Internal Server Error\"}"));
		break;
	case 503:
		LOG_ERR("Service Unavailable: %s", header_end + 4);
		memcpy(location_str, "{\"message\": \"Service Unavailable\"}",
		       sizeof("{\"message\": \"Service Unavailable\"}"));
		break;
	default:
		LOG_ERR("Unexpected HTTP response code: %d", http_response_code);
		memcpy(location_str, "{\"message\": \"Unexpected HTTP response code\"}",
		       sizeof("{\"message\": \"Unexpected HTTP response code\"}"));
		break;
	}
	if (ret < 0) {
		LOG_ERR("Failed to format location string\n");
		goto clean_up;
	}

clean_up:
	freeaddrinfo(res);
	(void)close(fd);
}
```

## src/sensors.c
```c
#include "sensors.h"

#include <zephyr/logging/log.h>
LOG_MODULE_REGISTER(SENSORS, CONFIG_SENSORS_LOG_LEVEL);

void sensor_gas_thread();

K_THREAD_STACK_DEFINE(gas_stack_area, 1024);
struct k_thread gas_thread_data;
k_tid_t gas_thread_id;

const struct device *dev_bmi270 = DEVICE_DT_GET(DT_ALIAS(accel0));
const struct device *dev_adxl367 = DEVICE_DT_GET(DT_ALIAS(accel1));
const struct device *dev_bme680 = DEVICE_DT_GET(DT_ALIAS(env0));
// const struct device *dev_bmm350 = DEVICE_DT_GET(DT_ALIAS(mag0)); // NOTE: The bmm350 device have
// no zephyr drivers yet

/**
 * @brief Rotate a measurement around an axis.
 *
 * @param val pointer to the sensor value.
 * @param angle angle to rotate in degrees.
 * @param axis axis to rotate around (0 = x, 1 = y, 2 = z).
 *
 * @return int 0 if successful, negative errno otherwise.
 */
int rotate_measurement(struct sensor_value *val, int angle, int axis)
{
	double angle_rad = angle * PI / 180.0;
	double cos_angle = cos(angle_rad);
	double sin_angle = sin(angle_rad);

	double x = sensor_value_to_double(&val[0]);
	double y = sensor_value_to_double(&val[1]);
	double z = sensor_value_to_double(&val[2]);

	double x_new = 0.0;
	double y_new = 0.0;
	double z_new = 0.0;

	if (axis == 0) {
		// Rotate around x-axis
		x_new = x;
		y_new = y * cos_angle - z * sin_angle;
		z_new = y * sin_angle + z * cos_angle;
	} else if (axis == 1) {
		// Rotate around y-axis
		x_new = x * cos_angle + z * sin_angle;
		y_new = y;
		z_new = -x * sin_angle + z * cos_angle;
	} else if (axis == 2) {
		// Rotate around z-axis
		x_new = x * cos_angle - y * sin_angle;
		y_new = x * sin_angle + y * cos_angle;
		z_new = z;
	} else {
		LOG_ERR("Invalid axis for rotation");
		return -EINVAL;
	}

	sensor_value_from_double(&val[0], x_new);
	sensor_value_from_double(&val[1], y_new);
	sensor_value_from_double(&val[2], z_new);

	return 0;
}

/**
 * @brief Initialize the sensors
 *
 * @return int 0 if successful, negative error code otherwise.
 */
int sensors_init(void)
{
	int ret;
	//////////////////////BMI270//////////////////////

	if (!device_is_ready(dev_bmi270)) {
		LOG_ERR("Device %s is not ready", dev_bmi270->name);
		return -1;
	}
	LOG_INF("Device %s is ready", dev_bmi270->name);

	struct sensor_value ful_scale, sampling_freq, oversampling;
	ful_scale.val1 = 2; /* G */
	ful_scale.val2 = 0;
	sampling_freq.val1 = 200; /* Hz */
	sampling_freq.val2 = 0;
	oversampling.val1 = 1; /* Normal mode */
	oversampling.val2 = 0;

	/* Set sampling frequency last as this also sets the appropriate
	 * power mode. If already sampling, change to 0.0Hz before changing
	 * other attributes
	 */
	sensor_attr_set(dev_bmi270, SENSOR_CHAN_ACCEL_XYZ, SENSOR_ATTR_FULL_SCALE, &ful_scale);
	sensor_attr_set(dev_bmi270, SENSOR_CHAN_ACCEL_XYZ, SENSOR_ATTR_OVERSAMPLING, &oversampling);
	sensor_attr_set(dev_bmi270, SENSOR_CHAN_ACCEL_XYZ, SENSOR_ATTR_SAMPLING_FREQUENCY,
			&sampling_freq);

	ful_scale.val1 = 1000; /* dps */
	ful_scale.val2 = 0;
	sampling_freq.val1 = 200; /* Hz. */
	sampling_freq.val2 = 0;
	oversampling.val1 = 2; /* Normal mode */
	oversampling.val2 = 0;

	/* Set sampling frequency last as this also sets the appropriate
	 * power mode. If already sampling, change to 0.0Hz before changing
	 * other attributes
	 */
	sensor_attr_set(dev_bmi270, SENSOR_CHAN_GYRO_XYZ, SENSOR_ATTR_FULL_SCALE, &ful_scale);
	sensor_attr_set(dev_bmi270, SENSOR_CHAN_GYRO_XYZ, SENSOR_ATTR_OVERSAMPLING, &oversampling);
	sensor_attr_set(dev_bmi270, SENSOR_CHAN_GYRO_XYZ, SENSOR_ATTR_SAMPLING_FREQUENCY,
			&sampling_freq);

	//////////////////////ADXL367/////////////////////

	if (!device_is_ready(dev_adxl367)) {
		LOG_ERR("Device %s is not ready", dev_adxl367->name);
		return -1;
	}
	LOG_INF("Device %s is ready", dev_adxl367->name);

	struct sensor_value sampling_freq2;
	sampling_freq2.val1 = 100; /* Hz */
	sampling_freq2.val2 = 0;

	ret = sensor_attr_set(dev_adxl367, SENSOR_CHAN_ACCEL_XYZ, SENSOR_ATTR_SAMPLING_FREQUENCY,
			      &sampling_freq2);
	if (ret) {
		LOG_ERR("sensor_attr_set failed ret %d", ret);
		return ret;
	}

	//////////////////////BME680//////////////////////

	if (!device_is_ready(dev_bme680)) {
		LOG_ERR("Device %s is not ready", dev_bme680->name);
		return -1;
	}
	LOG_INF("Device %s is ready", dev_bme680->name);

	// NOTE: The bmm350 device have no zephyr drivers yet
	//////////////////////BMM350//////////////////////
	// if(!device_is_ready(dev_bmm350)) {
	//     LOG_ERR("Device %s is not ready", dev_bmm350->name);
	//     return -1;
	// }
	// LOG_INF("Device %s is ready", dev_bmm350->name);

	// Start the gas sensor thread

	gas_thread_id = k_thread_create(&gas_thread_data, gas_stack_area,
					K_THREAD_STACK_SIZEOF(gas_stack_area), sensor_gas_thread,
					NULL, NULL, NULL, 7, 0, K_NO_WAIT);

	return 0;
}

struct sensor_value temp, press, hum, gas;
// Thread to measure the gas sensor continuously and update a global variable as the gas measurement
// are slow
void sensor_gas_thread()
{
	int ret;
	while (1) {
		//////////////////////BME680//////////////////////
		LOG_DBG("BME680");
		ret = sensor_sample_fetch(dev_bme680);
		if (ret) {
			LOG_ERR("sensor_sample_fetch failed ret %d", ret);
			return;
		}

		ret = sensor_channel_get(dev_bme680, SENSOR_CHAN_AMBIENT_TEMP, &temp);
		if (ret) {
			LOG_ERR("sensor_channel_get failed ret %d", ret);
			return;
		}

		ret = sensor_channel_get(dev_bme680, SENSOR_CHAN_PRESS, &press);
		if (ret) {
			LOG_ERR("sensor_channel_get failed ret %d", ret);
			return;
		}

		ret = sensor_channel_get(dev_bme680, SENSOR_CHAN_HUMIDITY, &hum);
		if (ret) {
			LOG_ERR("sensor_channel_get failed ret %d", ret);
			return;
		}

		ret = sensor_channel_get(dev_bme680, SENSOR_CHAN_GAS_RES, &gas);
		if (ret) {
			LOG_ERR("sensor_channel_get failed ret %d", ret);
			return;
		}

		k_sleep(K_MSEC(250));
	}
}

/**
 * @brief Meassure the sensor data
 *
 * @param data Pointer to the data array
 *       [timestamp,                                            \
 *       BMI270_accel_x, BMI270_accel_y, BMI270_accel_z,    \
 *       BMI270_gyro_x, BMI270_gyro_y, BMI270_gyro_z,       \
 *       ADXL367_accel_x, ADXL367_accel_y, ADXL367_accel_z, \
 *       BME680_temp, BME680_press, BME680_hum, BME680_gas, \
 *       BMM350_magn_x, BMM350_magn_y, BMM350_magn_z]
 *
 * All values are in SI units.
 *      Acceleration in m/s^2
 *      Gyroscope in rad/s
 *      Temperature in Celsius
 *      Pressure in Pascal
 *      Humidity in %
 *      Gas resistance in Ohm
 *      Magnetometer in uT // NOTE: The bmm350 device have no zephyr drivers yet, data will be 0
 *
 * @return 0 if successful, negative error code otherwise.
 */
int sensor_measure(double *data)
{
	int ret;
	struct sensor_value accel0[3], gyr[3];
	struct sensor_value accel1[3];
	// struct sensor_value temp, press, hum, gas;
	// struct sensor_value mag[3]; // NOTE: The bmm350 device have no zephyr drivers yet

	//////////////////////BMI270//////////////////////
	LOG_DBG("BMI270");
	ret = sensor_sample_fetch(dev_bmi270);
	if (ret) {
		LOG_ERR("sensor_sample_fetch failed ret %d", ret);
		return -1;
	}

	ret = sensor_channel_get(dev_bmi270, SENSOR_CHAN_ACCEL_XYZ, accel0);
	if (ret) {
		LOG_ERR("sensor_channel_get failed ret %d", ret);
		return -1;
	}

	ret = sensor_channel_get(dev_bmi270, SENSOR_CHAN_GYRO_XYZ, gyr);
	if (ret) {
		LOG_ERR("sensor_channel_get failed ret %d", ret);
		return -1;
	}

	// Rotate the BMI270 data to match the orientation of the thingy
	ret = rotate_measurement(accel0, 180, 2);
	if (ret) {
		LOG_ERR("rotate_measurement failed ret %d", ret);
		return -1;
	}

	ret = rotate_measurement(gyr, 180, 2);
	if (ret) {
		LOG_ERR("rotate_measurement failed ret %d", ret);
		return -1;
	}

	//////////////////////ADXL367/////////////////////
	LOG_DBG("ADXL367");
	ret = sensor_sample_fetch(dev_adxl367);
	if (ret) {
		LOG_ERR("sensor_sample_fetch failed ret %d", ret);
		return -1;
	}

	ret = sensor_channel_get(dev_adxl367, SENSOR_CHAN_ACCEL_XYZ, accel1);
	if (ret) {
		LOG_ERR("sensor_channel_get SENSOR_CHAN_ACCEL_XYZ failed ret %d", ret);
		return -1;
	}

	// //////////////////////BME680//////////////////////
	// LOG_DBG("BME680");
	// ret = sensor_sample_fetch(dev_bme680);
	// if (ret) {
	// 	LOG_ERR("sensor_sample_fetch failed ret %d", ret);
	// 	return -1;
	// }

	// ret = sensor_channel_get(dev_bme680, SENSOR_CHAN_AMBIENT_TEMP, &temp);
	// if (ret) {
	// 	LOG_ERR("sensor_channel_get failed ret %d", ret);
	// 	return -1;
	// }

	// ret = sensor_channel_get(dev_bme680, SENSOR_CHAN_PRESS, &press);
	// if (ret) {
	// 	LOG_ERR("sensor_channel_get failed ret %d", ret);
	// 	return -1;
	// }

	// ret = sensor_channel_get(dev_bme680, SENSOR_CHAN_HUMIDITY, &hum);
	// if (ret) {
	// 	LOG_ERR("sensor_channel_get failed ret %d", ret);
	// 	return -1;
	// }

	// ret = sensor_channel_get(dev_bme680, SENSOR_CHAN_GAS_RES, &gas);
	// if (ret) {
	// 	LOG_ERR("sensor_channel_get failed ret %d", ret);
	// 	return -1;
	// }

	// current_time = k_cycle_get_32();
	// diff = current_time - measure_start_time;
	// LOG_INF("BME680: %d us", k_cyc_to_us_floor32(diff));

	// NOTE: The bmm350 device have no zephyr drivers yet
	////////////////////BMM350//////////////////////
	// LOG_DBG("BMM350");
	// ret = sensor_sample_fetch(dev_bmm350);
	// if(ret) {
	//     LOG_ERR("sensor_sample_fetch failed ret %d", ret);
	//     return -1;
	// }

	// ret = sensor_channel_get(dev_bmm350, SENSOR_CHAN_MAGN_XYZ, mag);
	// if(ret) {
	//     LOG_ERR("sensor_channel_get failed ret %d", ret);
	//     return -1;
	// }

	LOG_DBG("Sensor data fetched");
	float32_t runtime = (float32_t)k_cycle_get_32() / (float32_t)sys_clock_hw_cycles_per_sec();

	// LOG_INF("Runtime: %f", runtime);

	//////////////////////Set output//////////////////////
	LOG_DBG("Set output");
	data[0] = runtime;
	data[1] = sensor_value_to_double(&accel0[0]);
	data[2] = sensor_value_to_double(&accel0[1]);
	data[3] = sensor_value_to_double(&accel0[2]);
	data[4] = sensor_value_to_double(&gyr[0]);
	data[5] = sensor_value_to_double(&gyr[1]);
	data[6] = sensor_value_to_double(&gyr[2]);
	data[7] = sensor_value_to_double(&accel1[0]);
	data[8] = sensor_value_to_double(&accel1[1]);
	data[9] = sensor_value_to_double(&accel1[2]);
	data[10] = sensor_value_to_double(&temp);
	data[11] = sensor_value_to_double(&press);
	data[12] = sensor_value_to_double(&hum);
	data[13] = sensor_value_to_double(&gas);
	// data[14] = sensor_value_to_double(&mag[0]);
	// data[15] = sensor_value_to_double(&mag[1]);
	// data[16] = sensor_value_to_double(&mag[2]);
	data[14] = 0.0;
	data[15] = 0.0;
	data[16] = 0.0;

	return 0;
}

/**
 * @brief Get the sensor data as a JSON string
 *      The JSON string will look like this:
 *      { "timestamp": 0.0, "bmi270_ax": 0.0, "bmi270_ay": 0.0, "bmi270_az": 0.0, "bmi270_gx": 0.0,
 *      "bmi270_gy": 0.0, "bmi270_gz": 0.0, "adxl_ax": 0.0, "adxl_ay": 0.0, "adxl_az": 0.0,
 *      "bme680_temperature": 0.0, "bme680_pressure": 0.0, "bme680_humidity": 0.0, "bme680_gas":
 * 0.0, "bmm350_magn_x": 0.0, "bmm350_magn_y": 0.0, "bmm350_magn_z": 0.0 }
 *
 * @param buf Pointer to the buffer
 * @param len Length of the buffer
 * @return int Length of the JSON string if successful, negative error code otherwise.
 */
int sensors_get_json(char *buf, size_t len)
{
	int ret;

	const char *sensors_json_template = "{"
					    "\"timestamp\":%.06f,"
					    "\"bmi270_ax\":%.06f,"
					    "\"bmi270_ay\":%.06f,"
					    "\"bmi270_az\":%.06f,"
					    "\"bmi270_gx\":%.06f,"
					    "\"bmi270_gy\":%.06f,"
					    "\"bmi270_gz\":%.06f,"
					    "\"adxl_ax\":%.06f,"
					    "\"adxl_ay\":%.06f,"
					    "\"adxl_az\":%.06f,"
					    "\"bme680_temperature\":%.03f,"
					    "\"bme680_pressure\":%.03f,"
					    "\"bme680_humidity\":%.03f,"
					    "\"bme680_gas\":%.03f,"
					    "\"bmm350_magn_x\":%.03f,"
					    "\"bmm350_magn_y\":%.03f,"
					    "\"bmm350_magn_z\":%.03f"
					    "}";

	LOG_DBG("Getting sensor data");

	double data[NUM_SENSOR_MEASUREMENTS];
	ret = sensor_measure(data);
	if (ret) {
		LOG_ERR("sensor_measure failed ret %d", ret);
		return ret;
	}

	LOG_DBG("Got sensor data");

	ret = snprintf(buf, len, sensors_json_template, data[0], data[1], data[2], data[3], data[4],
		       data[5], data[6], data[7], data[8], data[9], data[10], data[11], data[12],
		       data[13], data[14], data[15], data[16]);

	LOG_DBG("JSON-ified sensor data");
	// LOG_INF("JSON: %s", buf);

	if (ret >= len) {
		LOG_ERR("Sensor data does not fit in buffer");
		return -ENOSPC;
	}

	return ret;
}
```

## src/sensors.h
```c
#pragma once

#include <zephyr/kernel.h>
#include <zephyr/device.h>
#include <zephyr/drivers/sensor.h>
#include <math.h>

#define GRAVITY 9.80665
#define PI      3.14159265359

// Number of sensor measurements (timestamp, 6x bmi270, 3x adxl367, 4x bme680, 3x bmm350)
#define NUM_SENSOR_MEASUREMENTS 17

int sensors_init(void);
int sensors_measure(void);
int sensors_get_json(char *buf, size_t len);
int sensor_rotate_measurement(struct sensor_value *data, int x, int y, int z);
```

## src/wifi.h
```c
#pragma once

#include <zephyr/net/net_if.h>
#include <zephyr/net/wifi_mgmt.h>
#include <zephyr/net/wifi_utils.h>
#include <zephyr/net/net_event.h>
#include <zephyr/net/socket.h>
#include <net/wifi_mgmt_ext.h>
#include <net/wifi_ready.h>
#include <stdlib.h>

#define WIFI_SHELL_MGMT_EVENTS (NET_EVENT_WIFI_CONNECT_RESULT | NET_EVENT_WIFI_DISCONNECT_RESULT)
#define STATUS_POLLING_MS      300

void wifi_sta_set_wifi_connected_cb(void *cb);
int start_app(void);
k_tid_t wifi_sta_get_start_wifi_thread_id(void);
void net_mgmt_callback_init(void);
int register_wifi_ready(void);

int wifi_scan(void);
void get_nrfcloud_api_str(char *buf, size_t len);
```
